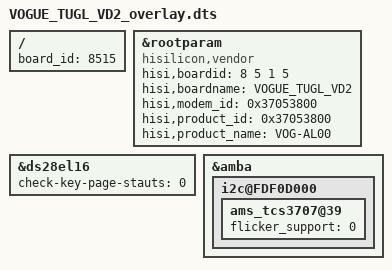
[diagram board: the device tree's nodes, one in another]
/**
 * Copyright (C) 2014 Hisilicon Ltd.
 *
 *  This program is free software; you can redistribute it and/or modify
 *  it under the terms of the GNU General Public License version 2 as
 *  publishhed by the Free Software Foundation.
 */

/dts-v1/;
/plugin/;
/include/ "VOGUE_TUGL_VD_overlay.dtsi"
/include/ "VOGUE_TUGL_VD2_pin.dtsi"
/include/ "VOGUE_TUGL_VD2_modem_pin.dtsi"

/ {
    board_id = <8515>;
};
    &rootparam{
		compatible = "hisilicon,vendor";
		hisi,boardid = <8 5 1 5>;
		hisi,boardname = "VOGUE_TUGL_VD2";
		hisi,modem_id = <0x37053800>;
		hisi,product_id = <0x37053800>;
		hisi,product_name = "VOG-AL00";
	};
	&ds28el16 {
		check-key-page-stauts = <0>;
	};
	&amba {
		i2c@FDF0D000 {
			ams_tcs3707@39 {
				flicker_support = <0>;
			};
		};
	};
